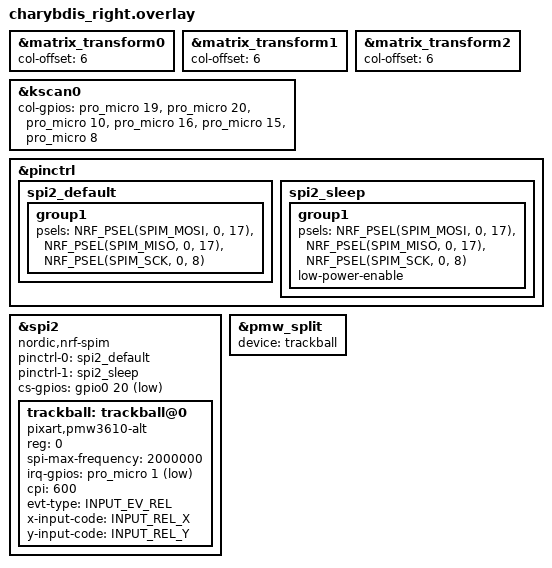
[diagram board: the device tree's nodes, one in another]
/*
 * Copyright (c) 2020 ZMK Contributors
 *
 * SPDX-License-Identifier: MIT
 */

#include "charybdis.dtsi"

&matrix_transform0 {
    col-offset = <6>;
};

&matrix_transform1 {
    col-offset = <6>;
};

&matrix_transform2 {
    col-offset = <6>;
};

&kscan0 {
    col-gpios
        = <&pro_micro 19 (GPIO_ACTIVE_HIGH | GPIO_PULL_DOWN)>
        , <&pro_micro 20 (GPIO_ACTIVE_HIGH | GPIO_PULL_DOWN)>
        , <&pro_micro 10 (GPIO_ACTIVE_HIGH | GPIO_PULL_DOWN)>
        , <&pro_micro 16 (GPIO_ACTIVE_HIGH | GPIO_PULL_DOWN)>
        , <&pro_micro 15 (GPIO_ACTIVE_HIGH | GPIO_PULL_DOWN)>
        , <&pro_micro 8 (GPIO_ACTIVE_HIGH | GPIO_PULL_DOWN)>
        ;
};

&pinctrl {
    spi2_default: spi2_default {
        group1 {
            psels = <NRF_PSEL(SPIM_MOSI, 0, 17)>,
                    <NRF_PSEL(SPIM_MISO, 0, 17)>,
                    <NRF_PSEL(SPIM_SCK, 0, 8)>;
        };
    };

    spi2_sleep: spi2_sleep {
        group1 {
            psels = <NRF_PSEL(SPIM_MOSI, 0, 17)>,
                    <NRF_PSEL(SPIM_MISO, 0, 17)>,
                    <NRF_PSEL(SPIM_SCK, 0, 8)>;
            low-power-enable;
        };
    };
};

#include <zephyr/dt-bindings/input/input-event-codes.h>

nice_view_spi: &spi2 {
    status = "okay";
    compatible = "nordic,nrf-spim";
    pinctrl-0 = <&spi2_default>;
    pinctrl-1 = <&spi2_sleep>;
    pinctrl-names = "default", "sleep";
    cs-gpios = <&gpio0 20 GPIO_ACTIVE_LOW>;

    trackball: trackball@0 {
        status = "okay";
        compatible = "pixart,pmw3610-alt";
        reg = <0>;
        spi-max-frequency = <2000000>;
        irq-gpios = <&pro_micro 1 (GPIO_ACTIVE_LOW | GPIO_PULL_UP)>;
        cpi = <600>;
        evt-type = <INPUT_EV_REL>;
        x-input-code = <INPUT_REL_X>;
        y-input-code = <INPUT_REL_Y>;
    };
};

&pmw_split {
    device = <&trackball>;
};
